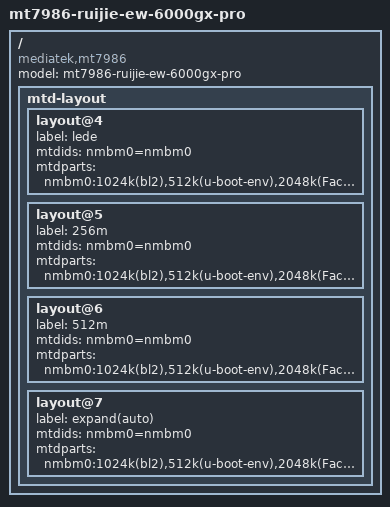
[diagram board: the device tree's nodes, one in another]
// SPDX-License-Identifier: GPL-2.0-or-later

/dts-v1/;
#include "mt7986a-ruijie-rg-x60.dtsi"

/ {
	model = "mt7986-ruijie-ew-6000gx-pro";
	compatible = "mediatek,mt7986", "mediatek,mt7986-rfb";

	mtd-layout {
		// layout@0..@3 由 mt7986a-ruijie-rg-x60.dtsi 提供（default/expand/stock/asuswrt），此处仅追加，勿复用其索引
		layout@4 {
			label = "lede";
			// lede/openwrt layout: single ubi, aligned to kernel ubi @6656k
			mtdids = "nmbm0=nmbm0";
			mtdparts = "nmbm0:1024k(bl2),512k(u-boot-env),2048k(Factory),2048k(fip),512k(product_info),512k(kdump),116224k(ubi)";
		};

		layout@5 {
			label = "256m";
			// for 256M spi-nand
			mtdids = "nmbm0=nmbm0";
			mtdparts = "nmbm0:1024k(bl2),512k(u-boot-env),2048k(Factory),2048k(fip),512k(product_info),512k(kdump),239104k(ubi)";
		};

		layout@6 {
			label = "512m";
			// for 512M spi-nand
			mtdids = "nmbm0=nmbm0";
			mtdparts = "nmbm0:1024k(bl2),512k(u-boot-env),2048k(Factory),2048k(fip),512k(product_info),512k(kdump),484864k(ubi)";
		};

		layout@7 {
			label = "expand(auto)";
			// ubi fills the whole flash, fits 128M/256M/512M
			mtdids = "nmbm0=nmbm0";
			mtdparts = "nmbm0:1024k(bl2),512k(u-boot-env),2048k(Factory),2048k(fip),512k(product_info),512k(kdump),-(ubi)";
		};
	};
};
